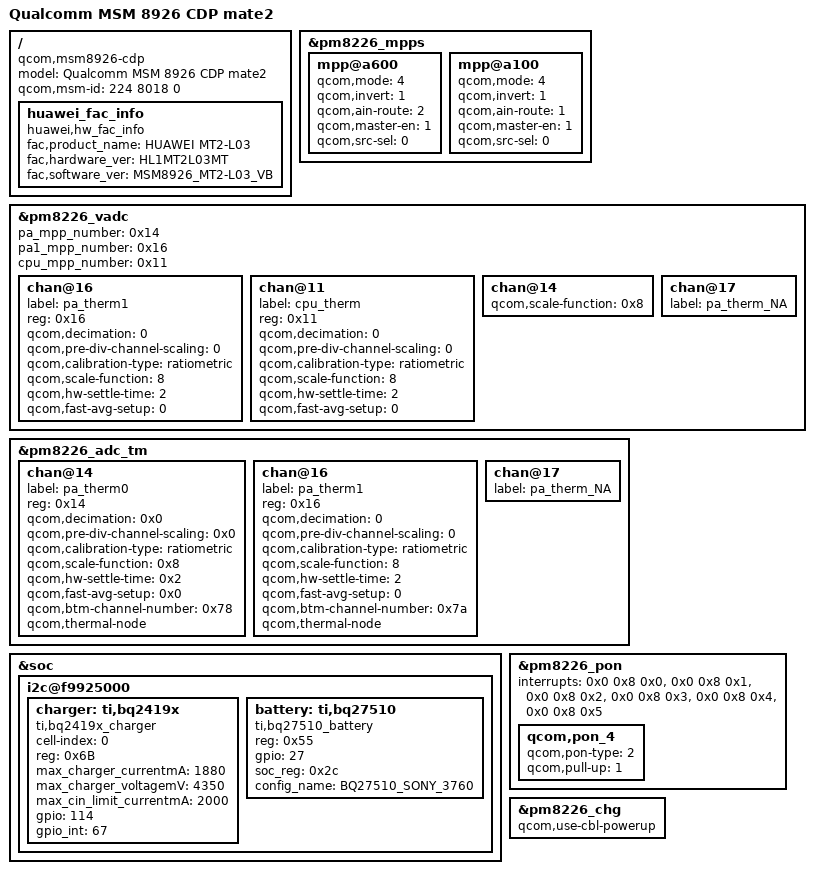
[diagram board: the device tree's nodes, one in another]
/* Copyright (c) 2013, The Linux Foundation. All rights reserved.
 *
 * This program is free software; you can redistribute it and/or modify
 * it under the terms of the GNU General Public License version 2 and
 * only version 2 as published by the Free Software Foundation.
 *
 * This program is distributed in the hope that it will be useful,
 * but WITHOUT ANY WARRANTY; without even the implied warranty of
 * MERCHANTABILITY or FITNESS FOR A PARTICULAR PURPOSE.  See the
 * GNU General Public License for more details.
 */


/dts-v1/;
/include/ "msm8926-v1.dtsi"
/include/ "msm8226-720p-cdp.dtsi"

/include/  "huawei_mate2-common/huawei-lcd.dtsi"
/include/  "huawei_mate2-common/huawei-sensors.dtsi"
/include/  "huawei_mate2-common/huawei-audio.dtsi"
/include/  "huawei_mate2-common/huawei-tp.dtsi"
/include/  "huawei_mate2-common/huawei-camera.dtsi"
/include/  "huawei_mate2-common/huawei-usb.dtsi"
/include/  "huawei_mate2-common/huawei-vibrator.dtsi"
/include/  "huawei_mate2-common/huawei-tricolor-led.dtsi"
/include/  "huawei_mate2-common/huawei-gpio.dtsi"

/ {
	model = "Qualcomm MSM 8926 CDP mate2";
	compatible = "qcom,msm8926-cdp", "qcom,msm8926", "qcom,cdp";
	qcom,msm-id = <224 8018 0>;

	huawei_fac_info {
		compatible = "huawei,hw_fac_info";
		fac,product_name = "HUAWEI MT2-L03";
		fac,hardware_ver = "HL1MT2L03MT";
		fac,software_ver = "MSM8926_MT2-L03_VB";
		status = "ok";
	};
};

&pm8226_mpps {
	mpp@a600 { /* MPP 7 */
		/* PA_THERM1 config */
		qcom,mode = <4>; /* AIN input */
		qcom,invert = <1>; /* Enable MPP */
		qcom,ain-route = <2>; /* AMUX 7 */
		qcom,master-en = <1>;
		qcom,src-sel = <0>; /* Function constant */
	};

	mpp@a100 { /* MPP 2 */
		/* PA_THERM1 config */
		qcom,mode = <4>; /* AIN input */
		qcom,invert = <1>; /* Enable MPP */
		qcom,ain-route = <1>; /* AMUX 6 */
		qcom,master-en = <1>;
		qcom,src-sel = <0>; /* Function constant */
	};
};

&pm8226_vadc {
	pa_mpp_number = <0x14>;
	pa1_mpp_number = <0x16>;
	cpu_mpp_number = <0x11>;

	chan@16 {
		label = "pa_therm1";
		reg = <0x16>;
		qcom,decimation = <0>;
		qcom,pre-div-channel-scaling = <0>;
		qcom,calibration-type = "ratiometric";
		qcom,scale-function = <8>;
		qcom,hw-settle-time = <2>;
		qcom,fast-avg-setup = <0>;
	};

	chan@11 {
		label = "cpu_therm";
		reg = <0x11>;
		qcom,decimation = <0>;
		qcom,pre-div-channel-scaling = <0>;
		qcom,calibration-type = "ratiometric";
		qcom,scale-function = <8>;
		qcom,hw-settle-time = <2>;
		qcom,fast-avg-setup = <0>;
	};

	chan@14 {
		qcom,scale-function = <0x8>;
	};

	chan@17 {
		label = "pa_therm_NA";
	};
};

&pm8226_adc_tm {
	chan@14 {
		label = "pa_therm0";
		reg = <0x14>;
		qcom,decimation = <0x0>;
		qcom,pre-div-channel-scaling = <0x0>;
		qcom,calibration-type = "ratiometric";
		qcom,scale-function = <0x8>;
		qcom,hw-settle-time = <0x2>;
		qcom,fast-avg-setup = <0x0>;
		qcom,btm-channel-number = <0x78>;
		qcom,thermal-node;
	};

	chan@16 {
		label = "pa_therm1";
		reg = <0x16>;
		qcom,decimation = <0>;
		qcom,pre-div-channel-scaling = <0>;
		qcom,calibration-type = "ratiometric";
		qcom,scale-function = <8>;
		qcom,hw-settle-time = <2>;
		qcom,fast-avg-setup = <0>;
		qcom,btm-channel-number = <0x7a>;
		qcom,thermal-node;
	};

	chan@17 {
		label = "pa_therm_NA";
	};
};

&soc{
	i2c@f9925000 {
		charger: ti,bq2419x {
			cell-index = <0>;
			compatible = "ti,bq2419x_charger";
			reg = <0x6B>;
			max_charger_currentmA = <1880>;
			max_charger_voltagemV = <4350>;
			max_cin_limit_currentmA = <2000>;
			gpio = <114>;
			gpio_int = <67>;
		};
	};

	i2c@f9925000 {
		battery: ti,bq27510 {
			compatible = "ti,bq27510_battery";
			reg = <0x55>;
			gpio = <27>;
			soc_reg = <0x2c>;
			config_name = "BQ27510_SONY_3760";
		};
	};
};

&pm8226_pon {
	interrupts = <0x0 0x8 0x0>,
		   <0x0 0x8 0x1>,
		   <0x0 0x8 0x2>,
		   <0x0 0x8 0x3>,
		   <0x0 0x8 0x4>,
		   <0x0 0x8 0x5>;
	interrupt-names = "kpdpwr", "resin", "cblpwr", "kpdpwr-bark",
		"resin-bark", "kpdpwr-resin-bark";

	qcom,pon_4 {
		qcom,pon-type = <2>;
		qcom,pull-up = <1>;
	};
};

&pm8226_chg {
	qcom,use-cbl-powerup;
};
